AUTOSAR XML (schema 3.1.2)
package /Components/SWC_AirSysTrb
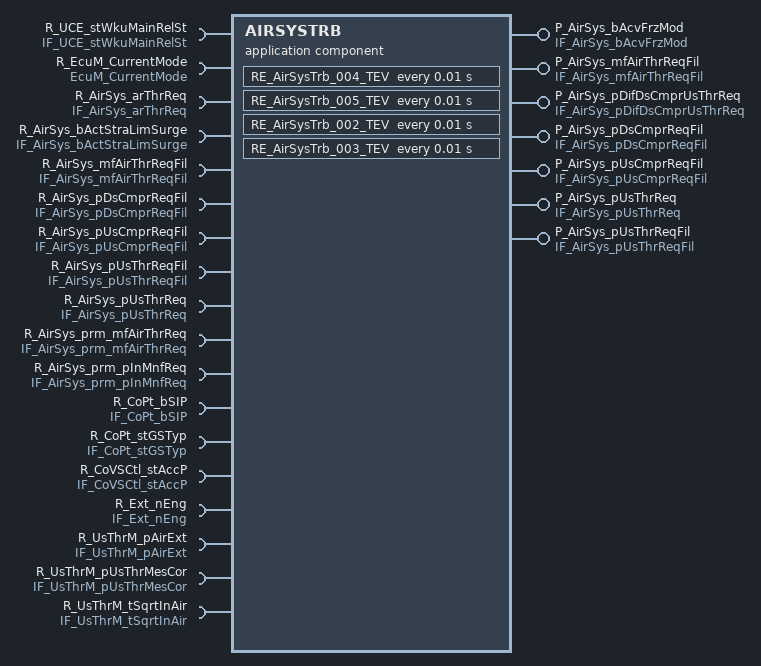
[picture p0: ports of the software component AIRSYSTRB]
  application software component type AIRSYSTRB  # AirSysTrb
    require port R_UCE_stWkuMainRelSt: required-interface=IF_UCE_stWkuMainRelSt
    7 x provide port:
      P_AirSys_bAcvFrzMod: unqueued-sender-com-spec{data-element=AirSys_bAcvFrzMod, can-invalidate=false, init-value=BooleanInitValue}, provided-interface=IF_AirSys_bAcvFrzMod
      P_AirSys_mfAirThrReqFil: unqueued-sender-com-spec{data-element=AirSys_mfAirThrReqFil, can-invalidate=false, init-value=UInt16InitValue}, provided-interface=IF_AirSys_mfAirThrReqFil
      P_AirSys_pDifDsCmprUsThrReq: unqueued-sender-com-spec{data-element=AirSys_pDifDsCmprUsThrReq, can-invalidate=false, init-value=SInt16InitValue}, provided-interface=IF_AirSys_pDifDsCmprUsThrReq
      P_AirSys_pDsCmprReqFil: unqueued-sender-com-spec{data-element=AirSys_pDsCmprReqFil, can-invalidate=false, init-value=UInt16InitValue1}, provided-interface=IF_AirSys_pDsCmprReqFil
      P_AirSys_pUsCmprReqFil: unqueued-sender-com-spec{data-element=AirSys_pUsCmprReqFil, can-invalidate=false, init-value=UInt16InitValue3}, provided-interface=IF_AirSys_pUsCmprReqFil
      P_AirSys_pUsThrReq: unqueued-sender-com-spec{data-element=AirSys_pUsThrReq, can-invalidate=false, init-value=UInt16InitValue5}, provided-interface=IF_AirSys_pUsThrReq
      P_AirSys_pUsThrReqFil: unqueued-sender-com-spec{data-element=AirSys_pUsThrReqFil, can-invalidate=false, init-value=UInt16InitValue7}, provided-interface=IF_AirSys_pUsThrReqFil
    17 x require port:
      R_EcuM_CurrentMode: required-interface=EcuM_CurrentMode
      R_AirSys_arThrReq: unqueued-receiver-com-spec{data-element=AirSys_arThrReq, init-value=UInt16InitValue9, resync-time=0}, required-interface=IF_AirSys_arThrReq
      R_AirSys_bActStraLimSurge: unqueued-receiver-com-spec{data-element=AirSys_bActStraLimSurge, init-value=BooleanInitValue11, resync-time=0}, required-interface=IF_AirSys_bActStraLimSurge
      R_AirSys_mfAirThrReqFil: unqueued-receiver-com-spec{data-element=AirSys_mfAirThrReqFil, init-value=UInt16InitValue, resync-time=0}, required-interface=IF_AirSys_mfAirThrReqFil
      R_AirSys_pDsCmprReqFil: unqueued-receiver-com-spec{data-element=AirSys_pDsCmprReqFil, init-value=UInt16InitValue13, resync-time=0}, required-interface=IF_AirSys_pDsCmprReqFil
      R_AirSys_pUsCmprReqFil: unqueued-receiver-com-spec{data-element=AirSys_pUsCmprReqFil, init-value=UInt16InitValue15, resync-time=0}, required-interface=IF_AirSys_pUsCmprReqFil
      R_AirSys_pUsThrReqFil: unqueued-receiver-com-spec{data-element=AirSys_pUsThrReqFil, init-value=UInt16InitValue17, resync-time=0}, required-interface=IF_AirSys_pUsThrReqFil
      R_AirSys_pUsThrReq: unqueued-receiver-com-spec{data-element=AirSys_pUsThrReq, init-value=UInt16InitValue19, resync-time=0}, required-interface=IF_AirSys_pUsThrReq
      R_AirSys_prm_mfAirThrReq: unqueued-receiver-com-spec{data-element=AirSys_prm_mfAirThrReq, init-value=rt_Array_UInt16_2InitValue, resync-time=0}, required-interface=IF_AirSys_prm_mfAirThrReq
      R_AirSys_prm_pInMnfReq: unqueued-receiver-com-spec{data-element=AirSys_prm_pInMnfReq, init-value=rt_Array_UInt16_2InitValue21, resync-time=0}, required-interface=IF_AirSys_prm_pInMnfReq
      R_CoPt_bSIP: unqueued-receiver-com-spec{data-element=CoPt_bSIP, init-value=BooleanInitValue23, resync-time=0}, required-interface=IF_CoPt_bSIP
      R_CoPt_stGSTyp: unqueued-receiver-com-spec{data-element=CoPt_stGSTyp, init-value=UInt8InitValue, resync-time=0}, required-interface=IF_CoPt_stGSTyp
      R_CoVSCtl_stAccP: unqueued-receiver-com-spec{data-element=CoVSCtl_stAccP, init-value=UInt8InitValue25, resync-time=0}, required-interface=IF_CoVSCtl_stAccP
      R_Ext_nEng: unqueued-receiver-com-spec{data-element=Ext_nEng, init-value=UInt16InitValue27, resync-time=0}, required-interface=IF_Ext_nEng
      R_UsThrM_pAirExt: unqueued-receiver-com-spec{data-element=UsThrM_pAirExt, init-value=UInt16InitValue29, resync-time=0}, required-interface=IF_UsThrM_pAirExt
      R_UsThrM_pUsThrMesCor: unqueued-receiver-com-spec{data-element=UsThrM_pUsThrMesCor, init-value=UInt16InitValue31, resync-time=0}, required-interface=IF_UsThrM_pUsThrMesCor
      R_UsThrM_tSqrtInAir: unqueued-receiver-com-spec{data-element=UsThrM_tSqrtInAir, init-value=UInt8InitValue33, resync-time=0}, required-interface=IF_UsThrM_tSqrtInAir
  24 x constant specification:
    BooleanInitValue
      value:
        boolean literal BooleanInitValue: type=DT_AirSys_bAcvFrzMod, value=false
    BooleanInitValue11
      value:
        boolean literal BooleanInitValue11: type=DT_AirSys_bActStraLimSurge, value=false
    BooleanInitValue23
      value:
        boolean literal BooleanInitValue23: type=DT_CoPt_bSIP, value=false
    InitValue_UInt16_0
      value:
        integer literal InitValue_UInt16_0: type=DT_AirSys_pDsCmprReq_irv, value=0
    InitValue_UInt16_035
      value:
        integer literal InitValue_UInt16_035: type=DT_AirSys_pUsCmprReq_irv, value=0
    rt_Array_UInt16_2InitValue
      value:
        array specification rt_Array_UInt16_2InitValue: type=rt_Array_UInt16_2_m1
          integer literal UInt16_1: type=DT_AirSys_prm_mfAirThrReq, value=0
          integer literal UInt16_2: type=DT_AirSys_prm_mfAirThrReq, value=0
    rt_Array_UInt16_2InitValue21
      value:
        array specification rt_Array_UInt16_2InitValue21: type=rt_Array_UInt16_2_m2
          integer literal UInt16_1: type=DT_AirSys_prm_pInMnfReq, value=0
          integer literal UInt16_2: type=DT_AirSys_prm_pInMnfReq, value=0
    SInt16InitValue
      value:
        integer literal SInt16InitValue: type=DT_AirSys_pDifDsCmprUsThrReq, value=0
    UInt16InitValue
      value:
        integer literal UInt16InitValue: type=DT_AirSys_mfAirThrReqFil, value=0
    UInt16InitValue1
      value:
        integer literal UInt16InitValue1: type=DT_AirSys_pDsCmprReqFil, value=0
    UInt16InitValue13
      value:
        integer literal UInt16InitValue13: type=DT_AirSys_pDsCmprReqFil, value=0
    UInt16InitValue15
      value:
        integer literal UInt16InitValue15: type=DT_AirSys_pUsCmprReqFil, value=0
    UInt16InitValue17
      value:
        integer literal UInt16InitValue17: type=DT_AirSys_pUsThrReqFil, value=0
    UInt16InitValue19
      value:
        integer literal UInt16InitValue19: type=DT_AirSys_pUsThrReq, value=0
    UInt16InitValue27
      value:
        integer literal UInt16InitValue27: type=DT_Ext_nEng, value=0
    UInt16InitValue29
      value:
        integer literal UInt16InitValue29: type=DT_UsThrM_pAirExt, value=0
    UInt16InitValue3
      value:
        integer literal UInt16InitValue3: type=DT_AirSys_pUsCmprReqFil, value=0
    UInt16InitValue31
      value:
        integer literal UInt16InitValue31: type=DT_UsThrM_pUsThrMesCor, value=0
    UInt16InitValue5
      value:
        integer literal UInt16InitValue5: type=DT_AirSys_pUsThrReq, value=0
    UInt16InitValue7
      value:
        integer literal UInt16InitValue7: type=DT_AirSys_pUsThrReqFil, value=0
    UInt16InitValue9
      value:
        integer literal UInt16InitValue9: type=DT_AirSys_arThrReq, value=0
    UInt8InitValue
      value:
        integer literal UInt8InitValue: type=DT_CoPt_stGSTyp, value=5
    UInt8InitValue25
      value:
        integer literal UInt8InitValue25: type=DT_CoVSCtl_stAccP, value=0
    UInt8InitValue33
      value:
        integer literal UInt8InitValue33: type=DT_UsThrM_tSqrtInAir, value=120
  internal behavior IB_AirSysTrb: component=AIRSYSTRB
    timing event EV_AirSysTrb_004_TEV: start-on-event=RE_AirSysTrb_004_TEV, period=0.01
    timing event EV_AirSysTrb_005_TEV: start-on-event=RE_AirSysTrb_005_TEV, period=0.01
    mode switch event EV_AirSysTrb_001_MSE: start-on-event=RE_AirSysTrb_001_MSE, activation=ENTRY, mode=R_EcuM_CurrentMode.currentMode.RUN
    timing event EV_AirSysTrb_002_TEV: start-on-event=RE_AirSysTrb_002_TEV, period=0.01
    timing event EV_AirSysTrb_003_TEV: start-on-event=RE_AirSysTrb_003_TEV, period=0.01
    inter runnable variable AirSys_pDsCmprReq_irv: sw-calibration-access=READ-WRITE, type=DT_AirSys_pDsCmprReq_irv, communication-approach=EXPLICIT, init-value=InitValue_UInt16_0
    inter runnable variable AirSys_pUsCmprReq_irv: sw-calibration-access=READ-WRITE, type=DT_AirSys_pUsCmprReq_irv, communication-approach=EXPLICIT, init-value=InitValue_UInt16_035
    5 x runnable:
      RE_AirSysTrb_002_TEV
        5 x data receive point:
          dr_UsThrM_tSqrtInAir: data-element=R_UsThrM_tSqrtInAir.UsThrM_tSqrtInAir
          dr_AirSys_prm_pInMnfReq: data-element=R_AirSys_prm_pInMnfReq.AirSys_prm_pInMnfReq
          dr_AirSys_prm_mfAirThrReq: data-element=R_AirSys_prm_mfAirThrReq.AirSys_prm_mfAirThrReq
          dr_AirSys_arThrReq: data-element=R_AirSys_arThrReq.AirSys_arThrReq
          dr_UsThrM_pAirExt: data-element=R_UsThrM_pAirExt.UsThrM_pAirExt
        data send point ds_AirSys_pUsThrReq: data-element=P_AirSys_pUsThrReq.AirSys_pUsThrReq
      RE_AirSysTrb_003_TEV: written-variable=AirSys_pUsCmprReq_irv
        data receive point dr_AirSys_prm_mfAirThrReq: data-element=R_AirSys_prm_mfAirThrReq.AirSys_prm_mfAirThrReq
        data receive point dr_UsThrM_pAirExt: data-element=R_UsThrM_pAirExt.UsThrM_pAirExt
      RE_AirSysTrb_005_TEV: read-variable=[AirSys_pUsCmprReq_irv, AirSys_pDsCmprReq_irv]
        11 x data receive point:
          dr_AirSys_prm_mfAirThrReq: data-element=R_AirSys_prm_mfAirThrReq.AirSys_prm_mfAirThrReq
          dr_CoPt_stGSTyp: data-element=R_CoPt_stGSTyp.CoPt_stGSTyp
          dr_AirSys_pUsThrReqFil: data-element=R_AirSys_pUsThrReqFil.AirSys_pUsThrReqFil
          dr_CoPt_bSIP: data-element=R_CoPt_bSIP.CoPt_bSIP
          dr_AirSys_bActStraLimSurge: data-element=R_AirSys_bActStraLimSurge.AirSys_bActStraLimSurge
          dr_AirSys_pUsCmprReqFil: data-element=R_AirSys_pUsCmprReqFil.AirSys_pUsCmprReqFil
          dr_AirSys_pUsThrReq: data-element=R_AirSys_pUsThrReq.AirSys_pUsThrReq
          dr_AirSys_mfAirThrReqFil: data-element=R_AirSys_mfAirThrReqFil.AirSys_mfAirThrReqFil
          dr_AirSys_pDsCmprReqFil: data-element=R_AirSys_pDsCmprReqFil.AirSys_pDsCmprReqFil
          dr_Ext_nEng: data-element=R_Ext_nEng.Ext_nEng
          dr_CoVSCtl_stAccP: data-element=R_CoVSCtl_stAccP.CoVSCtl_stAccP
        6 x data send point:
          ds_AirSys_mfAirThrReqFil: data-element=P_AirSys_mfAirThrReqFil.AirSys_mfAirThrReqFil
          ds_AirSys_pDsCmprReqFil: data-element=P_AirSys_pDsCmprReqFil.AirSys_pDsCmprReqFil
          ds_AirSys_pUsCmprReqFil: data-element=P_AirSys_pUsCmprReqFil.AirSys_pUsCmprReqFil
          ds_AirSys_pUsThrReqFil: data-element=P_AirSys_pUsThrReqFil.AirSys_pUsThrReqFil
          ds_AirSys_pDifDsCmprUsThrReq: data-element=P_AirSys_pDifDsCmprUsThrReq.AirSys_pDifDsCmprUsThrReq
          ds_AirSys_bAcvFrzMod: data-element=P_AirSys_bAcvFrzMod.AirSys_bAcvFrzMod
      RE_AirSysTrb_004_TEV: written-variable=AirSys_pDsCmprReq_irv
        data receive point dr_AirSys_prm_mfAirThrReq: data-element=R_AirSys_prm_mfAirThrReq.AirSys_prm_mfAirThrReq
        data receive point dr_AirSys_pUsThrReq: data-element=R_AirSys_pUsThrReq.AirSys_pUsThrReq
      RE_AirSysTrb_001_MSE: written-variable=[AirSys_pUsCmprReq_irv, AirSys_pDsCmprReq_irv]
        4 x data receive point:
          dr_UsThrM_pUsThrMesCor: data-element=R_UsThrM_pUsThrMesCor.UsThrM_pUsThrMesCor
          dr_AirSys_pUsThrReq: data-element=R_AirSys_pUsThrReq.AirSys_pUsThrReq
          dr_UsThrM_pAirExt: data-element=R_UsThrM_pAirExt.UsThrM_pAirExt
          dr_AirSys_prm_mfAirThrReq: data-element=R_AirSys_prm_mfAirThrReq.AirSys_prm_mfAirThrReq
        7 x data send point:
          ds_AirSys_pUsThrReq: data-element=P_AirSys_pUsThrReq.AirSys_pUsThrReq
          ds_AirSys_pDifDsCmprUsThrReq: data-element=P_AirSys_pDifDsCmprUsThrReq.AirSys_pDifDsCmprUsThrReq
          ds_AirSys_mfAirThrReqFil: data-element=P_AirSys_mfAirThrReqFil.AirSys_mfAirThrReqFil
          ds_AirSys_pUsCmprReqFil: data-element=P_AirSys_pUsCmprReqFil.AirSys_pUsCmprReqFil
          ds_AirSys_pUsThrReqFil: data-element=P_AirSys_pUsThrReqFil.AirSys_pUsThrReqFil
          ds_AirSys_bAcvFrzMod: data-element=P_AirSys_bAcvFrzMod.AirSys_bAcvFrzMod
          ds_AirSys_pDsCmprReqFil: data-element=P_AirSys_pDsCmprReqFil.AirSys_pDsCmprReqFil
  swc implementation Imp_AirSysTrb: code-generator=Real-Time Workshop Embedded Coder 5.5 (R2010a) 25-Jan-2010, programming-language=C, behavior=IB_AirSysTrb
    code-descriptors:
      code CodeDescriptor: type=SRC
        10 x xfile:
          AirSysTrb_h: url=AirSysTrb.h
          AirSysTrb_import_h: url=AirSysTrb_import.h
          AirSysTrb_Version_c: url=AirSysTrb_Version.c
          AirSysTrb_Def_c: url=AirSysTrb_Def.c
          AirSysTrb_Version_h: url=AirSysTrb_Version.h
          AirSysTrb_c: url=AirSysTrb.c
          AirSysTrb_types_h: url=AirSysTrb_types.h
          AirSysTrb_private_h: url=AirSysTrb_private.h
          AirSysTrb_data_c: url=AirSysTrb_data.c
          AirSysTrb_MemMap_h: url=AirSysTrb_MemMap.h
package /Components/SWC_AirSysTrb/AirSysTrb_IRVDatatypes
  integer type DT_AirSys_pDsCmprReq_irv: base-type=uint16, lower-limit=0, upper-limit=65535
  integer type DT_AirSys_pUsCmprReq_irv: base-type=uint16, lower-limit=0, upper-limit=65535
